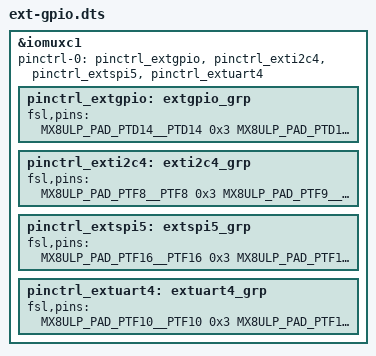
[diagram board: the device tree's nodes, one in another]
/*
 * Copyright 2022 AVNET
 *
 * This program is free software; you can redistribute it and/or
 * modify it under the terms of the GNU General Public License
 * as published by the Free Software Foundation; either version 2
 * of the License, or (at your option) any later version.
 *
 * This program is distributed in the hope that it will be useful,
 * but WITHOUT ANY WARRANTY; without even the implied warranty of
 * MERCHANTABILITY or FITNESS FOR A PARTICULAR PURPOSE.  See the
 * GNU General Public License for more details.
 */

/dts-v1/;
/plugin/;

#include "../imx8ulp-pinfunc.h"

/* 40-pin extended GPIO */

&iomuxc1 {
	pinctrl-0 = <&pinctrl_extgpio &pinctrl_exti2c4 &pinctrl_extspi5 &pinctrl_extuart4>;

	pinctrl_extgpio: extgpio_grp {
		fsl,pins = <
			MX8ULP_PAD_PTD14__PTD14		0x3 /* #07 */
			MX8ULP_PAD_PTD15__PTD15		0x3 /* #16 */
			MX8ULP_PAD_PTD16__PTD16		0x3 /* #18 */
			MX8ULP_PAD_PTD17__PTD17		0x3 /* #32 */
			MX8ULP_PAD_PTD18__PTD18		0x3 /* #40 */
			MX8ULP_PAD_PTD19__PTD19		0x3 /* #33 */
			MX8ULP_PAD_PTD20__PTD20		0x3 /* #15 */
			MX8ULP_PAD_PTD21__PTD21		0x3 /* #13 */
			MX8ULP_PAD_PTD22__PTD22		0x3 /* #11 */

			MX8ULP_PAD_PTE12__PTE12		0x3 /* #28 */
			MX8ULP_PAD_PTE13__PTE13		0x3 /* #27 */

			MX8ULP_PAD_PTF0__PTF0		0x3 /* #37 */
			MX8ULP_PAD_PTF1__PTF1		0x3 /* #29 */
			MX8ULP_PAD_PTF2__PTF2		0x3 /* #31 */
			MX8ULP_PAD_PTF3__PTF3		0x3 /* #22 */
			MX8ULP_PAD_PTF4__PTF4		0x3 /* #26 */
			MX8ULP_PAD_PTF5__PTF5		0x3 /* #36 */
			MX8ULP_PAD_PTF6__PTF6		0x3 /* #38 */
			MX8ULP_PAD_PTF25__PTF25		0x3 /* #12 */
			MX8ULP_PAD_PTF31__PTF31		0x3 /* #35 */
		>;
	};

	pinctrl_exti2c4: exti2c4_grp {
		fsl,pins = <
			MX8ULP_PAD_PTF8__PTF8		0x3 /* #03 */
			MX8ULP_PAD_PTF9__PTF9		0x3 /* #05 */
		>;
	};

	pinctrl_extspi5: extspi5_grp {
		fsl,pins = <
			MX8ULP_PAD_PTF16__PTF16		0x3 /* #19 */
			MX8ULP_PAD_PTF17__PTF17		0x3 /* #21 */
			MX8ULP_PAD_PTF18__PTF18		0x3 /* #23 */
			MX8ULP_PAD_PTF19__PTF19		0x3 /* #24 */
		>;
	};

	pinctrl_extuart4: extuart4_grp {
		fsl,pins = <
			MX8ULP_PAD_PTF10__PTF10		0x3 /* #08 */
			MX8ULP_PAD_PTF11__PTF11		0x3 /* #10 */
		>;
	};
};

